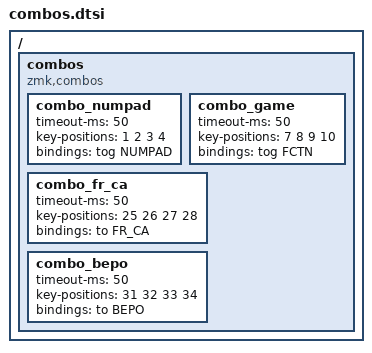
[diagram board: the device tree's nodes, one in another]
/ {
    combos {
        compatible = "zmk,combos";
        combo_numpad {
            timeout-ms = <50>;
            key-positions = < 1 2 3 4 >;
            bindings = <&tog NUMPAD>;
        };
        combo_game {
            timeout-ms = <50>;
            key-positions = < 7 8 9 10 >;
            bindings = <&tog FCTN>;
        };
        combo_fr_ca {
            timeout-ms = <50>;
            key-positions = < 25 26 27 28 >;
            bindings = <&to FR_CA>;
        };    
        combo_bepo {
            timeout-ms = <50>;
            key-positions = < 31 32 33 34 >;
            bindings = <&to BEPO>;
        };                
    };    
};
